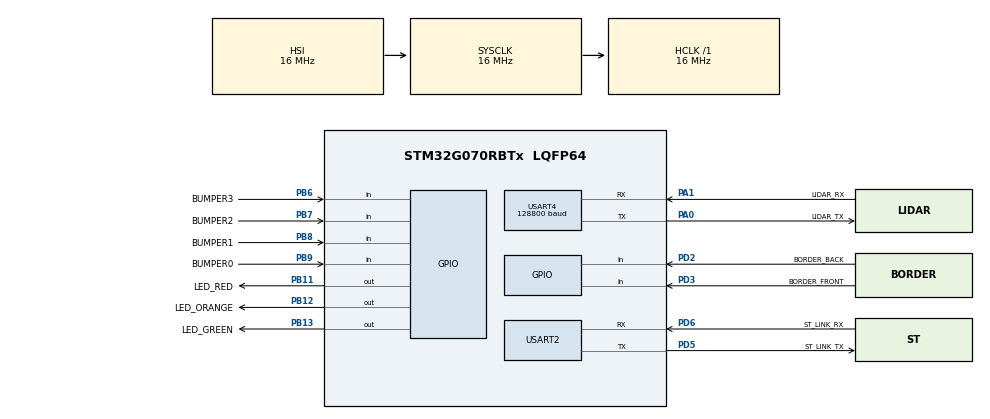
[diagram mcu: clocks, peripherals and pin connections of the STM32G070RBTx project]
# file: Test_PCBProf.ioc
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Mcu.Family=STM32G0
Mcu.Name=STM32G070RBTx
Mcu.Package=LQFP64
PA0.GPIO_Label=LIDAR_TX
PA0.Mode=Asynchronous
PA0.Signal=USART4_TX
PA1.GPIO_Label=LIDAR_RX
PA1.Mode=Asynchronous
PA1.Signal=USART4_RX
PB11.GPIO_Label=LED_RED
PB11.Signal=GPIO_Output
PB12.GPIO_Label=LED_ORANGE
PB12.Signal=GPIO_Output
PB13.GPIO_Label=LED_GREEN
PB13.Signal=GPIO_Output
PB6.GPIO_Label=BUMPER3
PB6.Signal=GPIO_Input
PB7.GPIO_Label=BUMPER2
PB7.Signal=GPIO_Input
PB8.GPIO_Label=BUMPER1
PB8.Signal=GPIO_Input
PB9.GPIO_Label=BUMPER0
PB9.Signal=GPIO_Input
PD2.GPIO_Label=BORDER_BACK
PD2.Signal=GPIO_Input
PD3.GPIO_Label=BORDER_FRONT
PD3.Signal=GPIO_Input
PD5.GPIO_Label=ST_LINK_TX
PD5.Mode=Asynchronous
PD5.Signal=USART2_TX
PD6.GPIO_Label=ST_LINK_RX
PD6.Mode=Asynchronous
PD6.Signal=USART2_RX
PF0-OSC_IN\ (PF0).Mode=HSE-External-Oscillator
PF0-OSC_IN\ (PF0).Signal=RCC_OSC_IN
PF1-OSC_OUT\ (PF1).Mode=HSE-External-Oscillator
PF1-OSC_OUT\ (PF1).Signal=RCC_OSC_OUT
ProjectManager.HeapSize=0x200
ProjectManager.StackSize=0x400
ProjectManager.TargetToolchain=STM32CubeIDE
RCC.AHBFreq_Value=16000000
RCC.CortexFreq_Value=16000000
RCC.EXTERNAL_CLOCK_VALUE=48000
RCC.HCLKFreq_Value=16000000
RCC.HSE_VALUE=8000000
RCC.HSI_VALUE=16000000
RCC.LSE_VALUE=32768
RCC.SYSCLKFreq_VALUE=16000000
RCC.VCOOutputFreq_Value=128000000
USART2.VirtualMode-Asynchronous=VM_ASYNC
USART4.BaudRate=128800
USART4.VirtualMode-Asynchronous=VM_ASYNC
board=custom

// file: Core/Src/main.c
/* USER CODE BEGIN Header */
/**
  ******************************************************************************
  * @file           : main.c
  * @brief          : Main program body
  ******************************************************************************
  * @attention
  *
  * Copyright (c) 2023 STMicroelectronics.
  * All rights reserved.
  *
  * This software is licensed under terms that can be found in the LICENSE file
  * in the root directory of this software component.
  * If no LICENSE file comes with this software, it is provided AS-IS.
  *
  ******************************************************************************
  */
/* USER CODE END Header */
#include "main.h"
#include "usart.h"
#include "gpio.h"

void SystemClock_Config(void);

/* USER CODE BEGIN 0 */
int __io_putchar(int chr)
{
	HAL_UART_Transmit(&huart2, (uint8_t*)&chr, 1, HAL_MAX_DELAY);
	return chr;
}

/* USER CODE END 0 */

int main(void)
{

  /* MCU Configuration--------------------------------------------------------*/

  /* Reset of all peripherals, Initializes the Flash interface and the Systick. */
  HAL_Init();

  /* Configure the system clock */
  SystemClock_Config();

  /* Initialize all configured peripherals */
  MX_GPIO_Init();
  MX_USART2_UART_Init();
  MX_USART4_UART_Init();
  /* USER CODE BEGIN 2 */
  HAL_GPIO_TogglePin(GPIOB, LED_GREEN_Pin);
  HAL_GPIO_TogglePin(GPIOB, LED_ORANGE_Pin);
  HAL_GPIO_TogglePin(GPIOB, LED_RED_Pin);
  HAL_Delay(1000);
  HAL_GPIO_WritePin(LED_GREEN_GPIO_Port, LED_GREEN_Pin, 0);
  HAL_GPIO_WritePin(LED_ORANGE_GPIO_Port, LED_ORANGE_Pin, 0);
  HAL_GPIO_WritePin(LED_RED_GPIO_Port, LED_RED_Pin, 0);
  /* USER CODE END 2 */

  /* Infinite loop */
  while (1)
  {

  }
}

void SystemClock_Config(void)
{
  RCC_OscInitTypeDef RCC_OscInitStruct = {0};
  RCC_ClkInitTypeDef RCC_ClkInitStruct = {0};

  /** Configure the main internal regulator output voltage
  */
  HAL_PWREx_ControlVoltageScaling(PWR_REGULATOR_VOLTAGE_SCALE1);

  /** Initializes the RCC Oscillators according to the specified parameters
  * in the RCC_OscInitTypeDef structure.
  */
  RCC_OscInitStruct.OscillatorType = RCC_OSCILLATORTYPE_HSI;
  RCC_OscInitStruct.HSIState = RCC_HSI_ON;
  RCC_OscInitStruct.HSIDiv = RCC_HSI_DIV1;
  RCC_OscInitStruct.HSICalibrationValue = RCC_HSICALIBRATION_DEFAULT;
  RCC_OscInitStruct.PLL.PLLState = RCC_PLL_NONE;
  if (HAL_RCC_OscConfig(&RCC_OscInitStruct) != HAL_OK)
  {
    Error_Handler();
  }

  /** Initializes the CPU, AHB and APB buses clocks
  */
  RCC_ClkInitStruct.ClockType = RCC_CLOCKTYPE_HCLK|RCC_CLOCKTYPE_SYSCLK
                              |RCC_CLOCKTYPE_PCLK1;
  RCC_ClkInitStruct.SYSCLKSource = RCC_SYSCLKSOURCE_HSI;
  RCC_ClkInitStruct.AHBCLKDivider = RCC_SYSCLK_DIV1;
  RCC_ClkInitStruct.APB1CLKDivider = RCC_HCLK_DIV1;

  if (HAL_RCC_ClockConfig(&RCC_ClkInitStruct, FLASH_LATENCY_0) != HAL_OK)
  {
    Error_Handler();
  }
}

void Error_Handler(void)
{
  __disable_irq();
  while (1)
  {
  }
}
